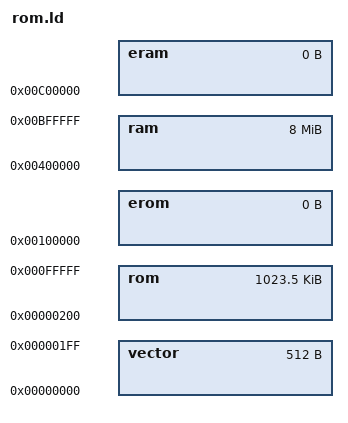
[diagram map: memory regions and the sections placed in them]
OUTPUT_ARCH(h8300s)
ENTRY("__start")

MEMORY 
	{
	vector : ORIGIN = 0x000000, LENGTH = 0x000200
	rom    : ORIGIN = 0x000200, LENGTH = 0x100000-0x000200
	erom   : ORIGIN = 0x100000, LENGTH = 0
	ram    : ORIGIN = 0x400000, LENGTH = 0xc00000-0x400000
	eram   : ORIGIN = 0xc00000, LENGTH = 0
	}
